# CC1312PSIP register map
File version: 1.0
CPU: CM4 1.0, other endian, MPU, FPU, 3 interrupt priority bits
Registers are 32-bit, read-write, reset 0x0 unless marked. A register's access mark holds for its fields unless they carry their own. Offsets are from the block's base; [hi:lo] are bit positions.

## PKA — Integrated module which combines the Public Key Acceleration module, optional True Random Gnerator, optional interrupt controller and a standard bus interface
Base 0x40025000
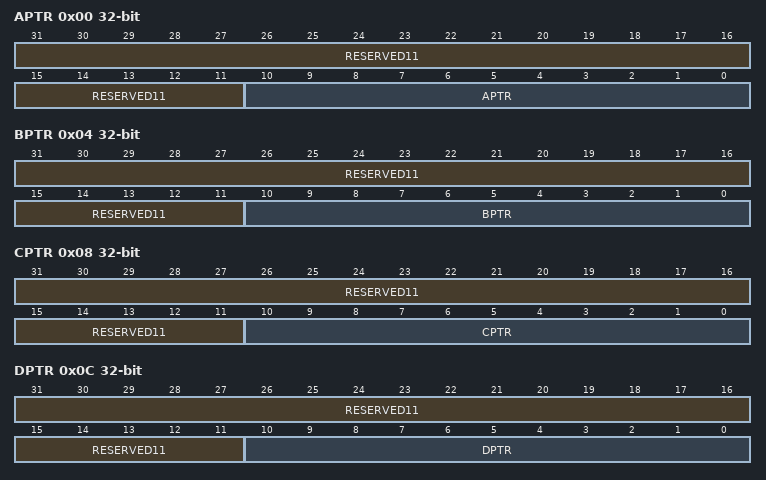
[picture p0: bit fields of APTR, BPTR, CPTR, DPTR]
0x00 APTR — PKA Vector A Address During execution of basic PKCP operations, this register is double buffered and can be written with a new value for the next operation; when not written, the value remains intact. During the execution of sequencer-controlled complex operations, this register may not be written and its value is undefined at the conclusion of the operation. The driver software cannot rely on the written value to remain intact.
  [31:11] RESERVED11 — [31:11] Set to zero on write, ignore on read
  [10:0] APTR — [10:0] This register specifies the location of vector A within the PKA RAM. Vectors are identified through the location of their least-significant 32-bit word. Note that bit [0] must be zero to ensure that the vector starts at an 8-byte boundary.
0x04 BPTR — PKA Vector B Address During execution of basic PKCP operations, this register is double buffered and can be written with a new value for the next operation; when not written, the value remains intact. During the execution of sequencer-controlled complex operations, this register may not be written and its value is undefined at the conclusion of the operation. The driver software cannot rely on the written value to remain intact.
  [31:11] RESERVED11 — [31:11] Set to zero on write, ignore on read
  [10:0] BPTR — [10:0] This register specifies the location of vector B within the PKA RAM. Vectors are identified through the location of their least-significant 32-bit word. Note that bit [0] must be zero to ensure that the vector starts at an 8-byte boundary.
0x08 CPTR — PKA Vector C Address During execution of basic PKCP operations, this register is double buffered and can be written with a new value for the next operation; when not written, the value remains intact. During the execution of sequencer-controlled complex operations, this register may not be written and its value is undefined at the conclusion of the operation. The driver software cannot rely on the written value to remain intact.
  [31:11] RESERVED11 — [31:11] Set to zero on write, ignore on read
  [10:0] CPTR — [10:0] This register specifies the location of vector C within the PKA RAM. Vectors are identified through the location of their least-significant 32-bit word. Note that bit [0] must be zero to ensure that the vector starts at an 8-byte boundary.
0x0C DPTR — PKA Vector D Address During execution of basic PKCP operations, this register is double buffered and can be written with a new value for the next operation; when not written, the value remains intact. During the execution of sequencer-controlled complex operations, this register may not be written and its value is undefined at the conclusion of the operation. The driver software cannot rely on the written value to remain intact.
  [31:11] RESERVED11 — [31:11] Set to zero on write, ignore on read
  [10:0] DPTR — [10:0] This register specifies the location of vector D within the PKA RAM. Vectors are identified through the location of their least-significant 32-bit word. Note that bit [0] must be zero to ensure that the vector starts at an 8-byte boundary.
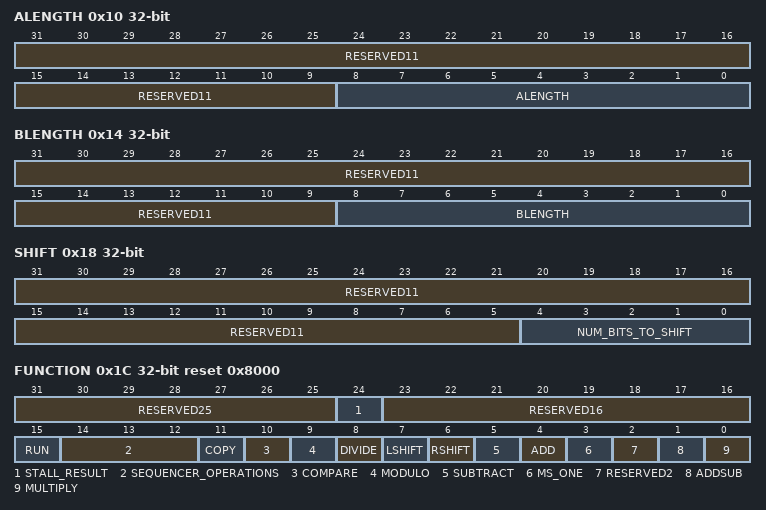
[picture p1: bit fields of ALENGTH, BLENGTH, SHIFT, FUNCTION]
0x10 ALENGTH — PKA Vector A Length During execution of basic PKCP operations, this register is double buffered and can be written with a new value for the next operation; when not written, the value remains intact. During the execution of sequencer-controlled complex operations, this register may not be written and its value is undefined at the conclusion of the operation. The driver software cannot rely on the written value to remain intact.
  [31:9] RESERVED11 — [31:9] Set to zero on write, ignore on read
  [8:0] ALENGTH — [8:0] This register specifies the length (in 32-bit words) of Vector A.
0x14 BLENGTH — PKA Vector B Length During execution of basic PKCP operations, this register is double buffered and can be written with a new value for the next operation; when not written, the value remains intact. During the execution of sequencer-controlled complex operations, this register may not be written and its value is undefined at the conclusion of the operation. The driver software cannot rely on the written value to remain intact.
  [31:9] RESERVED11 — [31:9] Set to zero on write, ignore on read
  [8:0] BLENGTH — [8:0] This register specifies the length (in 32-bit words) of Vector B.
0x18 SHIFT — PKA Bit Shift Value For basic PKCP operations, modifying the contents of this register is made impossible while the operation is being performed. For the ExpMod-variable and ExpMod-CRT operations, this register is used to indicate the number of odd powers to use (directly as a value in the range 1-16). For the ModInv and ECC operations, this register is used to hold a completion code.
  [31:5] RESERVED11 — [31:5] Set to zero on write, ignore on read
  [4:0] NUM_BITS_TO_SHIFT — [4:0] This register specifies the number of bits to shift the input vector (in the range 0-31) during a Rshift or Lshift operation.
0x1C FUNCTION reset 0x8000 — PKA Function This register contains the control bits to start basic PKCP as well as complex sequencer operations. The run bit can be used to poll for the completion of the operation. Modifying bits [11:0] is made impossible during the execution of a basic PKCP operation. During the execution of sequencer-controlled complex operations, this register is modified, the run and stall result bits are set to zero at the conclusion, but other bits are undefined. NOTE: Continuously reading this register to poll the run bit is not allowed when executing complex sequencer operations (the sequencer cannot access the PKCP when this is done). Leave at least one sysclk cycle between poll operations.
  [31:25] RESERVED25 — [31:25] Set to zero on write, ignore on read
  [24] STALL_RESULT — [24:24] When written with a 1b, updating of the COMPARE bit, MSW and DIVMSW registers, as well as resetting the run bit is stalled beyond the point that a running operation is actually finished. Use this to allow software enough time to read results from a previous operation when the newly started operation is known to take only a short amount of time. If a result is waiting, the result registers is updated and the run bit is reset in the clock cycle following writing the stall result bit back to 0b. The Stall result function may only be used for basic PKCP operations.
  [23:16] RESERVED16 — [23:16] Set to zero on write, ignore on read
  [15] RUN — [15:15] The host sets this bit to instruct the PKA module to begin processing the basic PKCP or complex sequencer operation. This bit is reset low automatically when the operation is complete. After a reset, the run bit is always set to 1b. Depending on the option, program ROM or program RAM, the following applies: Program ROM - The first sequencer instruction sets the bit to 0b. This is done immediately after the hardware reset is released. Program RAM - The sequencer must set the bit to 0b. As a valid firmware may not have been loaded, the sequencer is held in software reset after the hardware reset is released (the SEQCTRL.RESET bit is set to 1b). After the FW image is loaded and the Reset bit is cleared, the sequencer starts to execute the FW. The first instruction clears the run bit. In both cases a few clock cycles are needed before the first instruction is executed and the run bit state has been propagated.
  [14:12] SEQUENCER_OPERATIONS — [14:12] These bits select the complex sequencer operation to perform: 0x0: None 0x1: ExpMod-CRT 0x2: ECmontMUL 0x3: ECC-ADD (if available in firmware, otherwise reserved) 0x4: ExpMod-ACT2 0x5: ECC-MUL (if available in firmware, otherwise reserved) 0x6: ExpMod-variable 0x7: ModInv (if available in firmware, otherwise reserved) The encoding of these operations is determined by sequencer firmware.
  [11] COPY — [11:11] Perform copy operation
  [10] COMPARE — [10:10] Perform compare operation
  [9] MODULO — [9:9] Perform modulo operation
  [8] DIVIDE — [8:8] Perform divide operation
  [7] LSHIFT — [7:7] Perform left shift operation
  [6] RSHIFT — [6:6] Perform right shift operation
  [5] SUBTRACT — [5:5] Perform subtract operation
  [4] ADD — [4:4] Perform add operation
  [3] MS_ONE — [3:3] Loads the location of the Most Significant one bit within the result word indicated in the MSW register into bits [4:0] of the DIVMSW.MSW_ADDRESS register - can only be used with basic PKCP operations, except for Divide, Modulo and Compare.
  [2] RESERVED2 — [2:2] Set to zero on write, ignore on read
  [1] ADDSUB — [1:1] Perform combined add/subtract operation
  [0] MULTIPLY — [0:0] Perform multiply operation
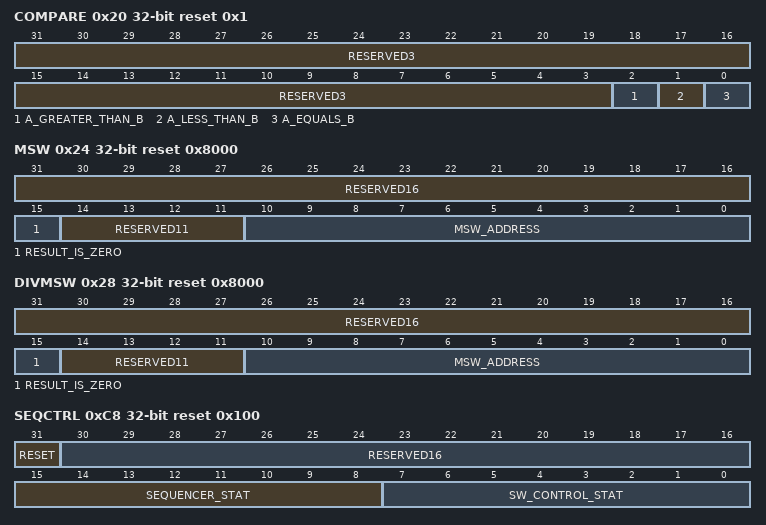
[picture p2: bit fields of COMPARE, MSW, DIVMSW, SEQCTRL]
0x20 COMPARE reset 0x1 — PKA compare result This register provides the result of a basic PKCP compare operation. It is updated when the FUNCTION.RUN bit is reset at the end of that operation. Status after a complex sequencer operation is unknown
  [31:3] RESERVED3 ro — [31:3] Ignore on read
  [2] A_GREATER_THAN_B ro — [2:2] Vector_A is greater than Vector_B
  [1] A_LESS_THAN_B ro — [1:1] Vector_A is less than Vector_B
  [0] A_EQUALS_B ro — [0:0] Vector_A is equal to Vector_B
0x24 MSW reset 0x8000 — PKA most-significant-word of result vector This register indicates the (word) address in the PKA RAM where the most significant nonzero 32-bit word of the result is stored. Should be ignored for modulo operations. For basic PKCP operations, this register is updated FUNCTION.RUN bit is reset at the end of the operation. For the complex-sequencer controlled operations, updating of the final value matching the actual result is done near the end of the operation; note that the result is only meaningful if no errors were detected and that for ECC operations, this register will provide information for the x-coordinate of the result point only.
  [31:16] RESERVED16 ro — [31:16] Ignore on read
  [15] RESULT_IS_ZERO ro — [15:15] The result vector is all zeroes, ignore the address returned in bits [10:0]
  [14:11] RESERVED11 ro — [14:11] Ignore on read
  [10:0] MSW_ADDRESS ro — [10:0] Address of the most-significant nonzero 32-bit word of the result vector in PKA RAM
0x28 DIVMSW reset 0x8000 — PKA most-significant-word of divide remainder This register indicates the (32-bit word) address in the PKA RAM where the most significant nonzero 32-bit word of the remainder result for the basic divide and modulo operations is stored. Bits [4:0] are loaded with the bit number of the most-significant nonzero bit in the most-significant nonzero word when MS one control bit is set. For divide, modulo, and MS one reporting, this register is updated when FUNCTION.RUN bit is reset at the end of the operation. For the complex sequencer controlled operations, updating of bits [4:0] of this register with the most-significant bit location of the actual result is done near the end of the operation. The result is meaningful only if no errors were detected and that for ECC operations; this register provides information for the x-coordinate of the result point only.
  [31:16] RESERVED16 ro — [31:16] Ignore on read
  [15] RESULT_IS_ZERO ro — [15:15] The result vector is all zeroes, ignore the address returned in bits [10:0]
  [14:11] RESERVED11 ro — [14:11] Ignore on read
  [10:0] MSW_ADDRESS ro — [10:0] Address of the most significant nonzero 32-bit word of the remainder result vector in PKA RAM
0xC8 SEQCTRL reset 0x100 — PKA sequencer control and status register The sequencer is interfaced with the outside world through a single control and status register. With the exception of bit [31], the actual use of bits in the separate sub-fields of this register is determined by the sequencer firmware. This register need only be accessed when the sequencer program is stored in RAM. The reset value of the RESET bit depends upon the option chosen for sequencer program storage. NOTE: For Agama the sequencer firmware is executed from ROM.
  [31] RESET — [31:31] Option program ROM: Reset value = 0. Read/Write, reset value 0b (ZERO). Writing 1b resets the sequencer, write to 0b to restart operations again. As the reset value is 0b, the sequencer will automatically start operations executing from program ROM. This bit should always be written with zero and ignored when reading this register. Option Program RAM: Reset value =1. Read/Write, reset value 1b (ONE). When 1b, the sequencer is held in a reset state and the PKA_PROGRAM area is accessible for loading the sequencer program (while the PKA_DATA_RAM is inaccessible), write to 0b to (re)start sequencer operations and disable PKA_PROGRAM area accessibility (also enables the PKA_DATA_RAM accesses). Resetting the sequencer (in order to load other firmware) should only be done when the PKA Engine is not performing any operations (i.e. the FUNCTION.RUN bit should be zero).
  [30:16] RESERVED16 — [30:16] Set to zero on write, ignore on read
  [15:8] SEQUENCER_STAT ro — [15:8] These read-only bits can be used by the sequencer to communicate status to the outside world. Bit [8] is also used as sequencer interrupt, with the complement of this bit ORed into the FUNCTION.RUN bit. This field should always be written with zeroes and ignored when reading this register.
  [7:0] SW_CONTROL_STAT — [7:0] These bits can be used by software to trigger sequencer operations. External logic can set these bits by writing 1b, cannot reset them by writing 0b. The sequencer can reset these bits by writing 0b, cannot set them by writing 1b. Setting the FUNCTION.RUN bit together with a nonzero sequencer operations field automatically sets bit [0] here. This field should always be written with zeroes and ignored when reading this register.
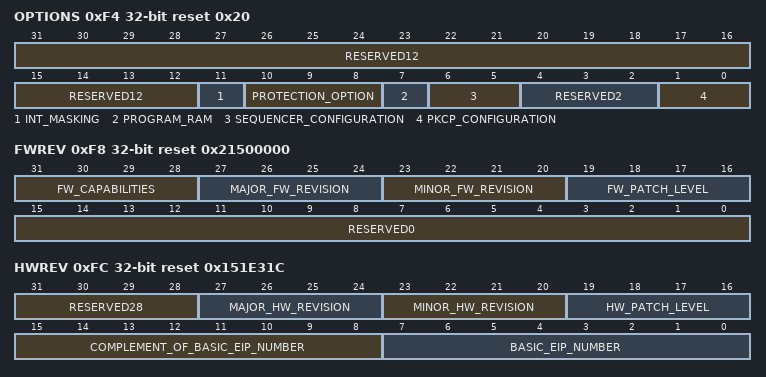
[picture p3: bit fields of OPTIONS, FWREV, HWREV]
0xF4 OPTIONS reset 0x20 — PKA hardware options register This register provides the host with a means to determine the hardware configuration implemented in this PKA engine, focused on options that have an effect on software interacting with the module.
  [31:12] RESERVED12 ro — [31:12] Ignore on read
  [11] INT_MASKING ro — [11:11] Interrupt Masking 0x0: indicates that the main interrupt output (bit [1] of the interrupts output bus) is the direct complement of the run bit in the PKA_CONTROL register, 0x1 : indicates that interrupt masking logic is present for this output. Note: Reset value is undefined
  [10:8] PROTECTION_OPTION ro — [10:8] Protection Option 0x0: indicates no additional protection against side channel attacks, 0x1: indicates the SCAP option 0x2: Reserved 0x3: indicates the PROT option; Note: Reset value is undefined
  [7] PROGRAM_RAM ro — [7:7] Program RAM 0x1: indicates sequencer program storage in RAM, 0x0: indicates sequencer program storage in ROM. Note: Reset value is undefined
  [6:5] SEQUENCER_CONFIGURATION ro — [6:5] Sequencer Configuration 0x0: Reserved 0x1 : Indicates a standard sequencer 0x2: Reserved 0x3: Reserved
  [4:2] RESERVED2 ro — [4:2] Ignore on read
  [1:0] PKCP_CONFIGURATION ro — [1:0] PKCP Configuration 0x0 : Reserved 0x1 : Indicates a PKCP with a 16x16 multiplier, 0x2: indicates a PKCP with a 32x32 multiplier, 0x3 : Reserved Note: Reset value is undefined.
0xF8 FWREV reset 0x21500000 — PKA firmware revision and capabilities register This register allows the host access to the internal firmware revision number of the PKA Engine for software driver matching and diagnostic purposes. This register also contains a field that encodes the capabilities of the embedded firmware. This register is written by the firmware within a few clock cycles after starting up that firmware. The hardware reset value is zero, indicating that the information has not been written yet.
  [31:28] FW_CAPABILITIES ro — [31:28] Firmware Capabilities 4-bit binary encoding for the functionality implemented in the firmware. 0x0: indicates basic ModExp with/without CRT. 0x1: adds Modular Inversion, 0x2: value 2 adds Modular Inversion and ECC operations. 0x3-0xF : Reserved.
  [27:24] MAJOR_FW_REVISION ro — [27:24] 4-bit binary encoding of the major firmware revision number
  [23:20] MINOR_FW_REVISION ro — [23:20] 4-bit binary encoding of the minor firmware revision number
  [19:16] FW_PATCH_LEVEL ro — [19:16] 4-bit binary encoding of the firmware patch level, initial release will carry value zero Patches are used to remove bugs without changing the functionality or interface of a module.
  [15:0] RESERVED0 ro — [15:0] Ignore on read
0xFC HWREV reset 0x151E31C — PKA hardware revision register This register allows the host access to the hardware revision number of the PKA engine for software driver matching and diagnostic purposes. It is always located at the highest address in the access space of the module and contains an encoding of the EIP number (with its complement as signature) for recognition of the hardware module.
  [31:28] RESERVED28 ro — [31:28] Ignore on read
  [27:24] MAJOR_HW_REVISION ro — [27:24] 4-bit binary encoding of the major hardware revision number
  [23:20] MINOR_HW_REVISION ro — [23:20] 4-bit binary encoding of the minor hardware revision number
  [19:16] HW_PATCH_LEVEL ro — [19:16] 4-bit binary encoding of the hardware patch level, initial release will carry value zero Patches are used to remove bugs without changing the functionality or interface of a module.
  [15:8] COMPLEMENT_OF_BASIC_EIP_NUMBER ro — [15:8] Bit-by-bit logic complement of bits [7:0], EIP-28 gives 0xE3
  [7:0] BASIC_EIP_NUMBER ro — [7:0] 8-bit binary encoding of the EIP number, EIP-28 gives 0x1C
